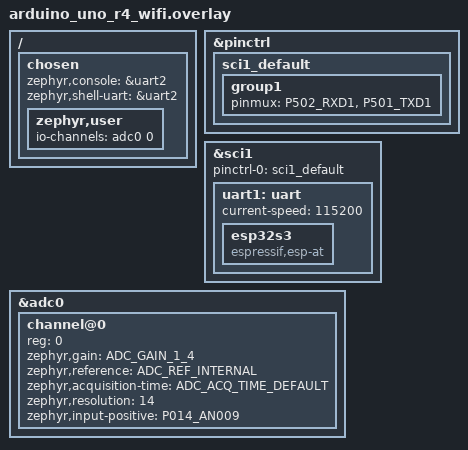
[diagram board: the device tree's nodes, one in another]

/ {
	chosen {
		zephyr,console = &uart2;
		zephyr,shell-uart = &uart2;
		zephyr,user {
			io-channels =
				<&adc0 0>;
		};
	};
};

&pinctrl {
	sci1_default: sci1_default {
		group1 {
			pinmux = <P502_RXD1>, <P501_TXD1>;
		};
	};

/*
	sci9_default: sci9_default {
		group1 {
			pinmux = <P110_RXD9>, <P109_TXD9>;
		};
	};
*/
};

&sci1 {
	status = "okay";
	pinctrl-0 = <&sci1_default>;
	pinctrl-names = "default";
	uart1: uart {
		current-speed = <115200>;
		status = "okay";

		esp32s3: esp32s3 {
			compatible = "espressif,esp-at";
//			status = "okay";			
		};
	};
};

/*
&sci9 { 
	pinctrl-0 = <&sci9_default>;
	pinctrl-names = "default";
	status = "okay";
	uart9: uart {
		current-speed = <115200>;		
		status = "okay";
	};
};
*/

&adc0 {
	status = "okay";
	#address-cells = <1>;
	#size-cells = <0>;

	channel@0 {
		reg = <0>;
		zephyr,gain = "ADC_GAIN_1_4";
		zephyr,reference = "ADC_REF_INTERNAL";
		zephyr,acquisition-time = <ADC_ACQ_TIME_DEFAULT>;
		zephyr,resolution = <14>;
		zephyr,input-positive = <P014_AN009>; 
	};
};
